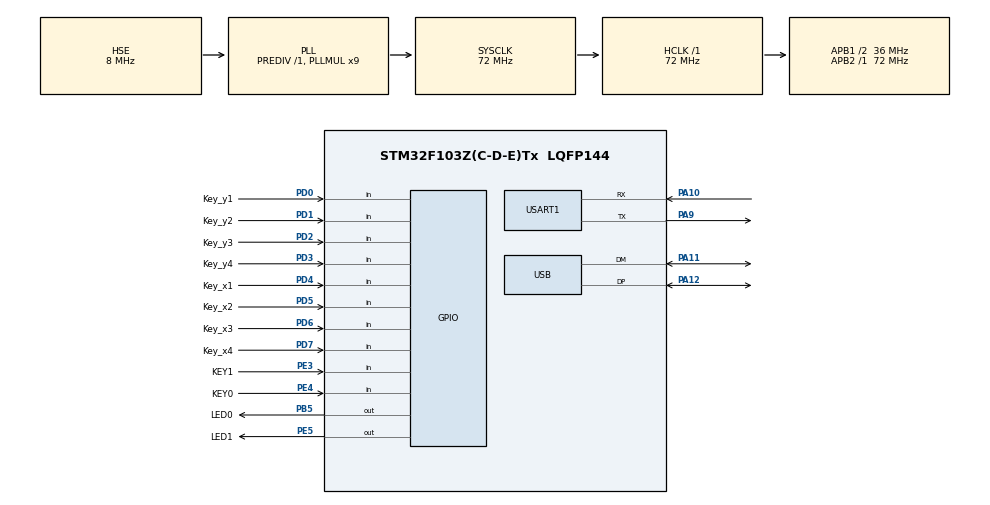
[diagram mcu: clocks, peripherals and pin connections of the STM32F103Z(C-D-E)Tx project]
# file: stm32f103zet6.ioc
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Mcu.Family=STM32F1
Mcu.Name=STM32F103Z(C-D-E)Tx
Mcu.Package=LQFP144
NVIC.PriorityGroup=NVIC_PRIORITYGROUP_4
NVIC.USART1_IRQn=true\:0\:0\:false\:false\:true\:true\:true
NVIC.USB_HP_CAN1_TX_IRQn=true\:0\:0\:false\:false\:true\:true\:true
NVIC.USB_LP_CAN1_RX0_IRQn=true\:0\:0\:false\:false\:true\:true\:true
OSC_IN.Mode=HSE-External-Oscillator
OSC_IN.Signal=RCC_OSC_IN
OSC_OUT.Mode=HSE-External-Oscillator
OSC_OUT.Signal=RCC_OSC_OUT
PA10.Mode=Asynchronous
PA10.Signal=USART1_RX
PA11.Mode=Device
PA11.Signal=USB_DM
PA12.Mode=Device
PA12.Signal=USB_DP
PA13.Mode=Serial_Wire
PA13.Signal=SYS_JTMS-SWDIO
PA14.Mode=Serial_Wire
PA14.Signal=SYS_JTCK-SWCLK
PA9.Mode=Asynchronous
PA9.Signal=USART1_TX
PB5.GPIO_Label=LED0
PB5.GPIO_PuPd=GPIO_PULLUP
PB5.PinState=GPIO_PIN_SET
PB5.Signal=GPIO_Output
PC14-OSC32_IN.Mode=LSE-External-Oscillator
PC14-OSC32_IN.Signal=RCC_OSC32_IN
PC15-OSC32_OUT.Mode=LSE-External-Oscillator
PC15-OSC32_OUT.Signal=RCC_OSC32_OUT
PD0.GPIO_Label=Key_y1
PD0.Signal=GPIO_Input
PD1.GPIO_Label=Key_y2
PD1.Signal=GPIO_Input
PD2.GPIO_Label=Key_y3
PD2.Signal=GPIO_Input
PD3.GPIO_Label=Key_y4
PD3.Signal=GPIO_Input
PD4.GPIO_Label=Key_x1
PD4.Signal=GPIO_Input
PD5.GPIO_Label=Key_x2
PD5.Signal=GPIO_Input
PD6.GPIO_Label=Key_x3
PD6.Signal=GPIO_Input
PD7.GPIO_Label=Key_x4
PD7.Signal=GPIO_Input
PE3.GPIO_Label=KEY1
PE3.GPIO_PuPd=GPIO_PULLUP
PE3.Signal=GPIO_Input
PE4.GPIO_Label=KEY0
PE4.GPIO_PuPd=GPIO_PULLUP
PE4.Signal=GPIO_Input
PE5.GPIO_Label=LED1
PE5.GPIO_PuPd=GPIO_PULLUP
PE5.PinState=GPIO_PIN_SET
PE5.Signal=GPIO_Output
ProjectManager.HeapSize=0x200
ProjectManager.StackSize=0x400
ProjectManager.TargetToolchain=STM32CubeIDE
RCC.AHBFreq_Value=72000000
RCC.APB1CLKDivider=RCC_HCLK_DIV2
RCC.APB1Freq_Value=36000000
RCC.APB1TimFreq_Value=72000000
RCC.APB2Freq_Value=72000000
RCC.APB2TimFreq_Value=72000000
RCC.HCLKFreq_Value=72000000
RCC.PLLMUL=RCC_PLL_MUL9
RCC.PLLSourceVirtual=RCC_PLLSOURCE_HSE
RCC.SYSCLKFreq_VALUE=72000000
RCC.SYSCLKSource=RCC_SYSCLKSOURCE_PLLCLK
RCC.USBFreq_Value=48000000
RCC.USBPrescaler=RCC_USBCLKSOURCE_PLL_DIV1_5
USART1.VirtualMode=VM_ASYNC
USB_DEVICE.CLASS_NAME_FS=CDC
USB_DEVICE.VirtualMode=Cdc
USB_DEVICE.VirtualModeFS=Cdc_FS
VP_CRC_VS_CRC.Mode=CRC_Activate
VP_USB_DEVICE_VS_USB_DEVICE_CDC_FS.Mode=CDC_FS
board=custom

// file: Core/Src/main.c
/* USER CODE BEGIN Header */
/**
  ******************************************************************************
  * @file           : main.c
  * @brief          : Main program body
  ******************************************************************************
  * @attention
  *
  * <h2><center>&copy; Copyright (c) 2021 STMicroelectronics.
  * All rights reserved.</center></h2>
  *
  * This software component is licensed by ST under BSD 3-Clause license,
  * the "License"; You may not use this file except in compliance with the
  * License. You may obtain a copy of the License at:
  *                        opensource.org/licenses/BSD-3-Clause
  *
  ******************************************************************************
  */
/* USER CODE END Header */
#include "main.h"
#include "crc.h"
#include "usart.h"
#include "usb_device.h"
#include "gpio.h"

/* USER CODE BEGIN Includes */
#include "modules.h"
/* USER CODE END Includes */

void SystemClock_Config(void);
/* USER CODE BEGIN PFP */
void timer1_callback(void);
void timer2_callback(void);
/* USER CODE END PFP */

int main(void)
{

  /* MCU Configuration--------------------------------------------------------*/

  /* Reset of all peripherals, Initializes the Flash interface and the Systick. */
  HAL_Init();

  /* Configure the system clock */
  SystemClock_Config();

  /* Initialize all configured peripherals */
  MX_GPIO_Init();
  MX_CRC_Init();
  MX_USART1_UART_Init();
  MX_USB_DEVICE_Init();
  /* USER CODE BEGIN 2 */

  HAL_GPIO_TogglePin(LED0_GPIO_Port, LED0_Pin);
  HAL_GPIO_TogglePin(LED1_GPIO_Port, LED1_Pin);
  HAL_Delay(5000);

  Multi_Timer_Init();
  Multi_Button_Init();
  /* USER CODE END 2 */

  /* Infinite loop */
  /* USER CODE BEGIN WHILE */
  printf("start\r\n");
  while (1)
  {
    /* USER CODE END WHILE */

    /* USER CODE BEGIN 3 */
	  timer_loop();
  }
  /* USER CODE END 3 */
}

void SystemClock_Config(void)
{
  RCC_OscInitTypeDef RCC_OscInitStruct = {0};
  RCC_ClkInitTypeDef RCC_ClkInitStruct = {0};
  RCC_PeriphCLKInitTypeDef PeriphClkInit = {0};

  /** Initializes the RCC Oscillators according to the specified parameters
  * in the RCC_OscInitTypeDef structure.
  */
  RCC_OscInitStruct.OscillatorType = RCC_OSCILLATORTYPE_HSE;
  RCC_OscInitStruct.HSEState = RCC_HSE_ON;
  RCC_OscInitStruct.HSEPredivValue = RCC_HSE_PREDIV_DIV1;
  RCC_OscInitStruct.HSIState = RCC_HSI_ON;
  RCC_OscInitStruct.PLL.PLLState = RCC_PLL_ON;
  RCC_OscInitStruct.PLL.PLLSource = RCC_PLLSOURCE_HSE;
  RCC_OscInitStruct.PLL.PLLMUL = RCC_PLL_MUL9;
  if (HAL_RCC_OscConfig(&RCC_OscInitStruct) != HAL_OK)
  {
    Error_Handler();
  }
  /** Initializes the CPU, AHB and APB buses clocks
  */
  RCC_ClkInitStruct.ClockType = RCC_CLOCKTYPE_HCLK|RCC_CLOCKTYPE_SYSCLK
                              |RCC_CLOCKTYPE_PCLK1|RCC_CLOCKTYPE_PCLK2;
  RCC_ClkInitStruct.SYSCLKSource = RCC_SYSCLKSOURCE_PLLCLK;
  RCC_ClkInitStruct.AHBCLKDivider = RCC_SYSCLK_DIV1;
  RCC_ClkInitStruct.APB1CLKDivider = RCC_HCLK_DIV2;
  RCC_ClkInitStruct.APB2CLKDivider = RCC_HCLK_DIV1;

  if (HAL_RCC_ClockConfig(&RCC_ClkInitStruct, FLASH_LATENCY_2) != HAL_OK)
  {
    Error_Handler();
  }
  PeriphClkInit.PeriphClockSelection = RCC_PERIPHCLK_USB;
  PeriphClkInit.UsbClockSelection = RCC_USBCLKSOURCE_PLL_DIV1_5;
  if (HAL_RCCEx_PeriphCLKConfig(&PeriphClkInit) != HAL_OK)
  {
    Error_Handler();
  }
}

void Error_Handler(void)
{
  __disable_irq();
  while (1)
  {
  }
}

/************************ (C) COPYRIGHT STMicroelectronics *****END OF FILE****/
